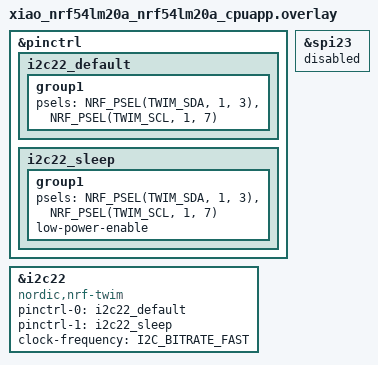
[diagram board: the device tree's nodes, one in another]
/*
 * I2C Speed Test - Device Tree Overlay for XIAO nRF54LM20A
 * BME280 @ 0x76 on I2C22
 * I2C Bus: i2c22 (SDA: P1.3, SCL: P1.7)
 */

&pinctrl {
	i2c22_default: i2c22_default {
		group1 {
			psels = <NRF_PSEL(TWIM_SDA, 1, 3)>,
				<NRF_PSEL(TWIM_SCL, 1, 7)>;
		};
	};

	i2c22_sleep: i2c22_sleep {
		group1 {
			psels = <NRF_PSEL(TWIM_SDA, 1, 3)>,
				<NRF_PSEL(TWIM_SCL, 1, 7)>;
			low-power-enable;
		};
	};
};

&i2c22 {
	compatible = "nordic,nrf-twim";
	status = "okay";
	pinctrl-0 = <&i2c22_default>;
	pinctrl-1 = <&i2c22_sleep>;
	pinctrl-names = "default", "sleep";
	/* Start with Fast mode, will be changed dynamically */
	clock-frequency = <I2C_BITRATE_FAST>;
};

&spi23 {
	status = "disabled";
};
